# RFCORE_XREG register map
Vendor: Texas Instruments
Peripheral module from a debugger description file (folder cc2538).
Registers are 32-bit, access per field, no defined reset value unless marked. A register's access mark holds for its fields unless they carry their own. Offsets are as the file gives them; lines under a group give offsets from that group; [hi:lo] are bit positions; {n}, {i} and the like mark numbered series; 'fields as' and 'values as' point back to an identical list; <NAME> marks a mode.

## RFCORE_XREG — Register fields should be considered static unless otherwise noted as dynamic.
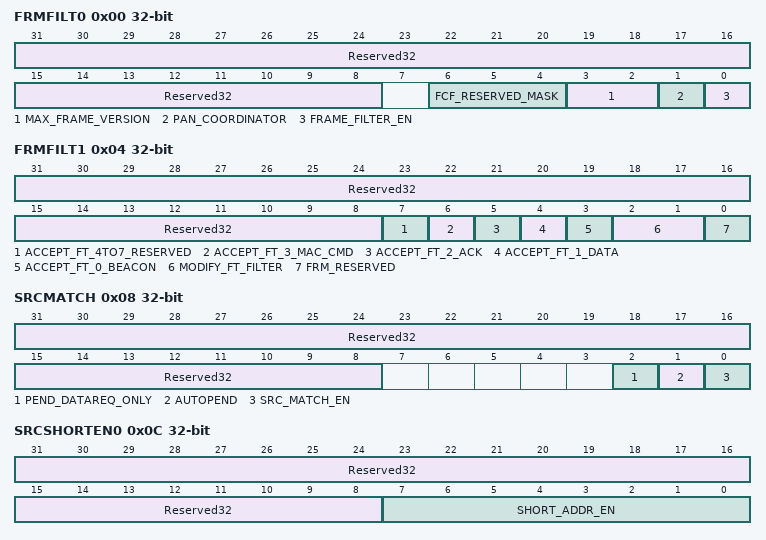
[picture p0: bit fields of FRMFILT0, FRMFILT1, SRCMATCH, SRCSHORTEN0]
0x00 FRMFILT0 — The frame filtering function rejects unintended frames as specified by IEEE 802.15.4, section 7.5.6.2, third filtering level. In addition, it provides filtering on: - The eight different frame types (see the FRMFILT1 register) - The reserved bits in the frame control field (FCF) The function is controlled by: - The FRMFILT0 and FRMFILT1 registers - The PAN_ID, SHORT_ADDR, and EXT_ADDR values in RAM
  [31:8] Reserved32 ro — This register is 8 bits in a 32-bit address space.
  [6:4] FCF_RESERVED_MASK rw — Used for filtering on the reserved part of the frame control field (FCF) FCF_RESERVED_MASK[2:0] is ANDed with FCF[9:7]. If the result is nonzero and frame filtering is enabled, the frame is rejected.
  [3:2] MAX_FRAME_VERSION rw — Used for filtering on the frame version field of the frame control field (FCF) If FCF[13:12] (the frame version subfield) is higher than MAX_FRAME_VERSION[1:0] and frame filtering is enabled, the frame is rejected.
  [1] PAN_COORDINATOR rw — Should be set high when the device is a PAN coordinator, to accept frames with no destination address (as specified in Section 7.5.6.2 in IEEE 802.15.4) 0: Device is not a PAN coordinator 1: Device is a PAN coordinator
  [0] FRAME_FILTER_EN rw — Enables frame filtering When this bit is set, the radio performs frame filtering as specified in section 7.5.6.2 of IEEE 802.15.4(b), third filtering level. FRMFILT0[6:1] and FRMFILT1[7:1], together with the local address information, define the behavior of the filtering algorithm. 0: Frame filtering off. (FRMFILT0[6:1], FRMFILT1[7:1] and SRCMATCH[2:0] are don't care.) 1: Frame filtering on.
0x04 FRMFILT1 — The frame filtering function rejects unintended frames as specified by IEEE 802.15.4, section 7.5.6.2, third filtering level. In addition, it provides filtering on: - The eight different frame types (see the FRMFILT1 register) - The reserved bits in the frame control field (FCF) The function is controlled by: - The FRMFILT0 and FRMFILT1 registers - The PAN_ID, SHORT_ADDR, and EXT_ADDR values in RAM
  [31:8] Reserved32 ro — This register is 8 bits in a 32-bit address space.
  [7] ACCEPT_FT_4TO7_RESERVED rw — Defines whether reserved frames are accepted or not. Reserved frames have frame type = 100, 101, 110, or 111. 0: Reject 1: Accept
  [6] ACCEPT_FT_3_MAC_CMD rw — Defines whether MAC command frames are accepted or not. MAC command frames have frame type = 011. 0: Reject 1: Accept
  [5] ACCEPT_FT_2_ACK rw — Defines whether acknowledgment frames are accepted or not. Acknowledgement frames have frame type = 010. 0: Reject 1: Accept
  [4] ACCEPT_FT_1_DATA rw — Defines whether data frames are accepted or not. Data frames have frame type = 001. 0: Reject 1: Accept
  [3] ACCEPT_FT_0_BEACON rw — Defines whether beacon frames are accepted or not. Beacon frames have frame type = 000. 0: Reject 1: Accept
  [2:1] MODIFY_FT_FILTER rw — These bits are used to modify the frame type field of a received frame before frame type filtering is performed. The modification does not influence the frame that is written to the RX FIFO. 00: Leave the frame type as it is. 01: Invert MSB of the frame type. 10: Set MSB of the frame type to 0. 11: Set MSB of the frame type to 1.
  [0] FRM_RESERVED rw — Reserved. Always write 0.
0x08 SRCMATCH — Source address matching and pending bits
  [31:8] Reserved32 ro — This register is 8 bits in a 32-bit address space.
  [2] PEND_DATAREQ_ONLY rw — When this bit is set, the AUTOPEND function also requires that the received frame is a DATA REQUEST MAC command frame.
  [1] AUTOPEND rw — Automatic acknowledgment pending flag enable When a frame is received, the pending bit in the (possibly) returned acknowledgment is set automatically when the following conditions are met: - FRMFILT.FRAME_FILTER_EN is set. - SRCMATCH.SRC_MATCH_EN is set. - SRCMATCH.AUTOPEND is set. - The received frame matches the current SRCMATCH.PEND_DATAREQ_ONLY setting. - The received source address matches at least one source match table entry, which is enabled in SHORT_ADDR_EN and SHORT_PEND_EN or in EXT_ADDR_EN and EXT_PEND_EN.
  [0] SRC_MATCH_EN rw — Source address matching enable (requires that FRMFILT.FRAME_FILTER_EN = 1)
0x0C SRCSHORTEN0 — Short address matching
  [31:8] Reserved32 ro — This register is 8 bits in a 32-bit address space.
  [7:0] SHORT_ADDR_EN rw — 7:0 part of the 24-bit word SHORT_ADDR_EN that enables or disables source address matching for each of the 24 short address table entries Optional safety feature: To ensure that an entry in the source matching table is not used while it is being updated, set the corresponding SHORT_ADDR_EN bit to 0 while updating.
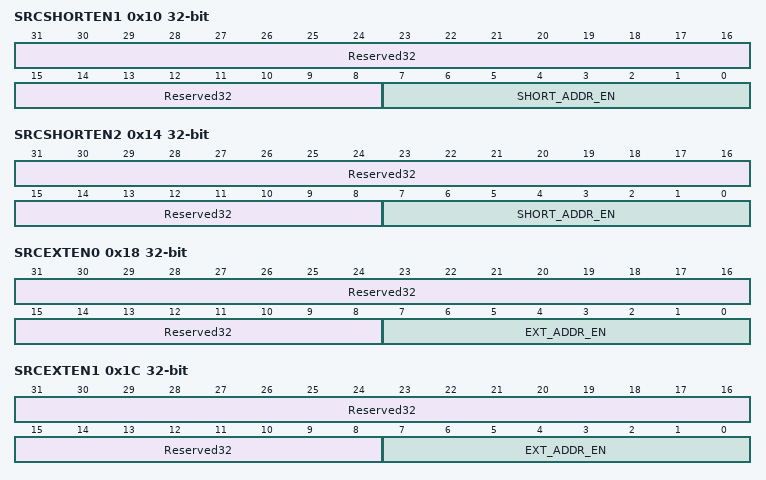
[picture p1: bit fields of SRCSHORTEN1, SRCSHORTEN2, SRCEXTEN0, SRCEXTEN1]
0x10 SRCSHORTEN1 — Short address matching
  [31:8] Reserved32 ro — This register is 8 bits in a 32-bit address space.
  [7:0] SHORT_ADDR_EN rw — 15:8 part of the 24-bit word SHORT_ADDR_EN See description of SRCSHORTEN0.SHORT_ADDR_EN.
0x14 SRCSHORTEN2 — Short address matching
  [31:8] Reserved32 ro — This register is 8 bits in a 32-bit address space.
  [7:0] SHORT_ADDR_EN rw — 23:16 part of the 24-bit word SHORT_ADDR_EN See description of SRCSHORTEN0.SHORT_ADDR_EN.
0x18 SRCEXTEN0 — Extended address matching
  [31:8] Reserved32 ro — This register is 8 bits in a 32-bit address space.
  [7:0] EXT_ADDR_EN rw — 7:0 part of the 24-bit word EXT_ADDR_EN that enables or disables source address matching for each of the 12 extended address table entries Write access: Extended address enable for table entry n (0 to 11) is mapped to EXT_ADDR_EN[2n]. All EXT_ADDR_EN[2n + 1] bits are read only. Read access: Extended address enable for table entry n (0 to 11) is mapped to EXT_ADDR_EN[2n] and EXT_ADDR_EN[2n + 1]. Optional safety feature: To ensure that an entry in the source matching table is not used while it is being updated, set the corresponding EXT_ADDR_EN bit to 0 while updating.
0x1C SRCEXTEN1 — Extended address matching
  [31:8] Reserved32 ro — This register is 8 bits in a 32-bit address space.
  [7:0] EXT_ADDR_EN rw — 15:8 part of the 24-bit word EXT_ADDR_EN See description of SRCEXTEN0.EXT_ADDR_EN.
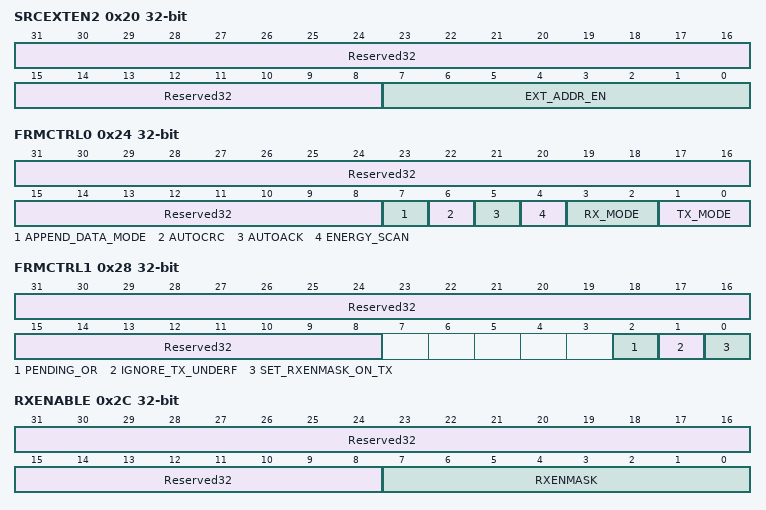
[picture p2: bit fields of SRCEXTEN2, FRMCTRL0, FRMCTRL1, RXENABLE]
0x20 SRCEXTEN2 — Extended address matching
  [31:8] Reserved32 ro — This register is 8 bits in a 32-bit address space.
  [7:0] EXT_ADDR_EN rw — 23:16 part of the 24-bit word EXT_ADDR_EN See description of SRCEXTEN0.EXT_ADDR_EN.
0x24 FRMCTRL0 — Frame handling
  [31:8] Reserved32 ro — This register is 8 bits in a 32-bit address space.
  [7] APPEND_DATA_MODE rw — When AUTOCRC = 0: Don't care When AUTOCRC = 1: 0: RSSI + The CRC_OK bit and the 7-bit correlation value are appended at the end of each received frame 1: RSSI + The CRC_OK bit and the 7-bit SRCRESINDEX are appended at the end of each received frame.
  [6] AUTOCRC rw — In TX 1: A CRC-16 (ITU-T) is generated in hardware and appended to the transmitted frame. There is no need to write the last 2 bytes to TXBUF. 0: No CRC-16 is appended to the frame. The last 2 bytes of the frame must be generated manually and written to TXBUF (if not, TX_UNDERFLOW occurs). In RX 1: The CRC-16 is checked in hardware, and replaced in the RXFIFO by a 16-bit status word which contains a CRC OK bit. The status word is controllable through APPEND_DATA_MODE. 0: The last 2 bytes of the frame (CRC-16 field) are stored in the RX FIFO. The CRC (if any) must be done manually. This setting does not influence acknowledgment transmission (including AUTOACK).
  [5] AUTOACK rw — Defines whether the radio automatically transmits acknowledge frames or not. When autoack is enabled, all frames that are accepted by address filtering, have the acknowledge request flag set, and have a valid CRC are automatically acknowledged 12 symbol periods after being received. 0: Autoack disabled 1: Autoack enabled
  [4] ENERGY_SCAN rw — Defines whether the RSSI register contains the most-recent signal strength or the peak signal strength since the energy scan was enabled. 0: Most-recent signal strength 1: Peak signal strength
  [3:2] RX_MODE rw — Set RX modes. 00: Normal operation, use RX FIFO 01: Receive serial mode, output received data on to IOC; infinite RX 10: RX FIFO looping ignore overflow in RX FIFO; infinite reception 11: Same as normal operation except that symbol search is disabled. Can be used for RSSI or CCA measurements when finding symbol is not desired.
  [1:0] TX_MODE rw — Set test modes for TX. 00: Normal operation, transmit TX FIFO 01: Reserved, should not be used 10: TX FIFO looping ignore underflow in TX FIFO and read cyclic; infinite transmission 11: Send random data from CRC; infinite transmission
0x28 FRMCTRL1 rw — Frame handling
  [31:8] Reserved32 — This register is 8 bits in a 32-bit address space.
  [2] PENDING_OR — Defines whether the pending data bit in outgoing acknowledgment frames is always set to 1 or controlled by the main FSM and the address filtering 0: Pending data bit is controlled by main FSM and address filtering. 1: Pending data bit is always 1.
  [1] IGNORE_TX_UNDERF — Defines whether or not TX underflow should be ignored 0: Normal TX operation. TX underflow is detected and TX is aborted if underflow occurs. 1: Ignore TX underflow. Transmit the number of bytes given by the frame-length field.
  [0] SET_RXENMASK_ON_TX — Defines whether STXON sets bit 6 in the RXENABLE register or leaves it unchanged 0: Does not affect RXENABLE 1: Sets bit 6 in RXENABLE. Used for backward compatibility with the CC2420.
0x2C RXENABLE ro — RX enabling
  [31:8] Reserved32 — This register is 8 bits in a 32-bit address space.
  [7:0] RXENMASK — RXENABLE enables the receiver. A nonzero value in this register causes FFCTRL to enable the receiver when in idle, after transmission and after acknowledgement transmission. The following strobes can modify RXENMASK: SRXON: Set bit 7 in RXENMASK. STXON: Set bit 6 in RXENMASK if SET_RXENMASK_ON_TX = 1. SRFOFF: Clears all bits in RXENMASK. SRXMASKBITSET: Set bit 5 in RXENMASK. SRXMASKBITCLR: Clear bit 5 in RXENMASK. There could be conflicts between the CSP and xreg_bus write operations if both operations try to modify RXENMASK simultaneously. To handle the case of simultaneous access to RXENMASK the following rules apply: - If the two sources agree (they modify different parts of the register) both of their requests to modify RXENMASK are processed. - If both operations try to modify the mask simultaneously, bus write operations to RXMASKSET and RXMASKCLR have priority over the CSP. This situation must be avoided.
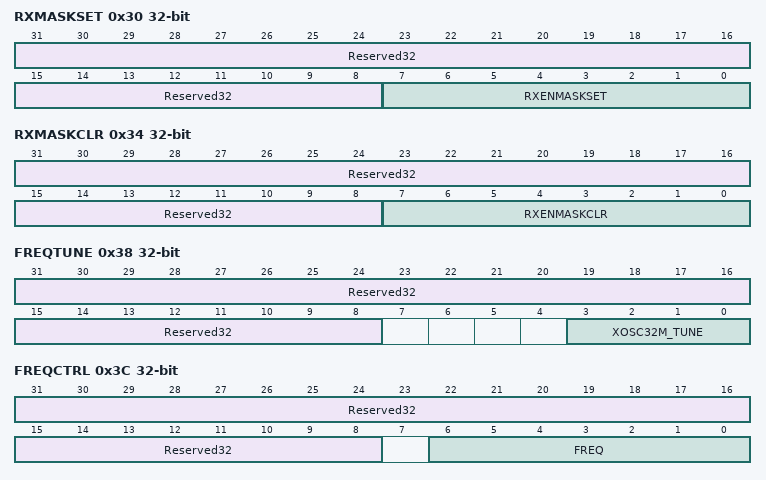
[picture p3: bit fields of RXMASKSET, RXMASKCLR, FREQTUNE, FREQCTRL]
0x30 RXMASKSET — RX enabling
  [31:8] Reserved32 ro — This register is 8 bits in a 32-bit address space.
  [7:0] RXENMASKSET rw — When written, the written data is ORed with the RXENMASK and stored in RXENMASK.
0x34 RXMASKCLR — RX disabling
  [31:8] Reserved32 ro — This register is 8 bits in a 32-bit address space.
  [7:0] RXENMASKCLR rw — When written, the written data is inverted and ANDed with the RXENMASK and stored in RXENMASK. For example, if 1 is written to one or more bit positions in this register, the corresponding bits are cleared in RXENMASK.
0x38 FREQTUNE — Crystal oscillator frequency tuning
  [31:8] Reserved32 ro — This register is 8 bits in a 32-bit address space.
  [3:0] XOSC32M_TUNE rw — Tune crystal oscillator The default setting 1111 leaves the XOSC untuned. Changing the setting from the default setting (1111) switches in extra capacitance to the oscillator, effectively lowering the XOSC frequency. Hence, a higher setting gives a higher frequency.
0x3C FREQCTRL — Controls the RF frequency
  [31:8] Reserved32 ro — This register is 8 bits in a 32-bit address space.
  [6:0] FREQ rw — Frequency control word The frequency word in FREQ[6:0] is an offset value from 2394 (fRF = FREQ[6 0] + 2394). The RF-frequency is specified from 2405 to 2480 MHz in 1-MHz steps; hence, the only valid settings for FREQ[6:0] are 11 to 86 (11 + 2394 = 2405 and 86 + 2394 = 2480). The device supports the frequency range from 2394 to 2507 MHz. Consequently, the usable settings for FREQ[6:0] are 0 to 113. Settings outside of the usable range (114 to 127) give a frequency of 2507 MHz. IEEE 802.15.4-2006 specifies a frequency range from 2405 MHz to 2480 MHz with 16 channels 5 MHz apart. The channels are numbered 11 through 26. For an IEEE 802.15.4-2006 compliant system, the only valid settings are thus FREQ[6:0] = 11 + 5 (channel number - 11).
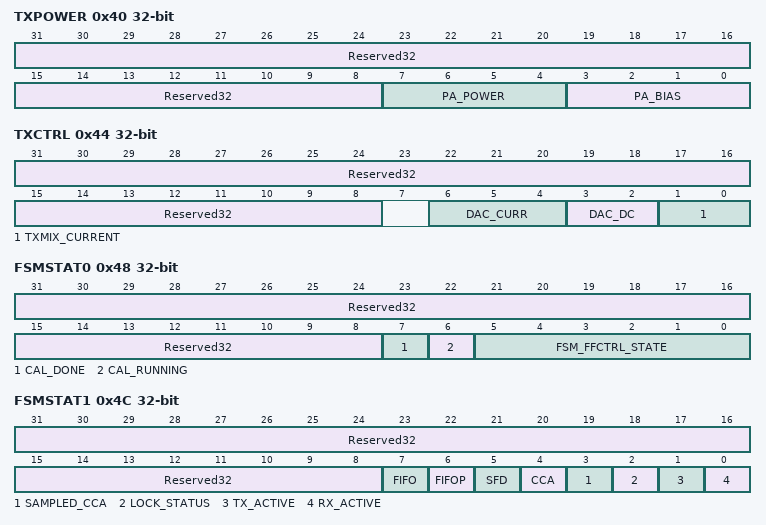
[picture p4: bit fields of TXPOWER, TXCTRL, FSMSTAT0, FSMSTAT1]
0x40 TXPOWER access not given — Controls the output power
  [31:8] Reserved32 ro — This register is 8 bits in a 32-bit address space.
  [7:4] PA_POWER — PA power control (access NA)
  [3:0] PA_BIAS rw — PA bias control
0x44 TXCTRL — Controls the TX settings
  [31:8] Reserved32 ro — This register is 8 bits in a 32-bit address space.
  [6:4] DAC_CURR rw — Change the current in the DAC.
  [3:2] DAC_DC rw — Adjusts the DC level to the TX mixer.
  [1:0] TXMIX_CURRENT rw — Transmit mixers core current Current increases with increasing setting.
0x48 FSMSTAT0 ro — Radio status register
  [31:8] Reserved32 — This register is 8 bits in a 32-bit address space.
  [7] CAL_DONE — Frequency synthesis calibration has been performed since the last time the FS was turned on.
  [6] CAL_RUNNING — Frequency synthesis calibration status 0: Calibration is complete or not started. 1: Calibration is in progress.
  [5:0] FSM_FFCTRL_STATE — Gives the current state of the FIFO and frame control (FFCTRL) finite state-machine.
0x4C FSMSTAT1 ro — Radio status register
  [31:8] Reserved32 — This register is 8 bits in a 32-bit address space.
  [7] FIFO — FIFO is high when there is data in the RX FIFO. FIFO is low during RX FIFO overflow.
  [6] FIFOP — FIFOP is set high when there are at more than FIFOP_THR bytes of data in the RX FIFO that has passed frame filtering. FIFOP is set high when there is at least one complete frame in the RX FIFO. FIFOP is high during RX FIFO overflow.
  [5] SFD — In TX 0: When a complete frame with SFD was sent or no SFD was sent 1: SFD was sent. In RX 0: When a complete frame was received or no SFD was received 1: SFD was received.
  [4] CCA — Clear channel assessment Dependent on CCA_MODE settings. See CCACTRL1 for details.
  [3] SAMPLED_CCA — Contains a sampled value of the CCA The value is updated when a SSAMPLECCA or STXONCCA strobe is issued.
  [2] LOCK_STATUS — 1 when PLL is in lock; otherwise 0
  [1] TX_ACTIVE — Status signal Active when FFC is in one of the transmit states
  [0] RX_ACTIVE — Status signal Active when FFC is in one of the receive states
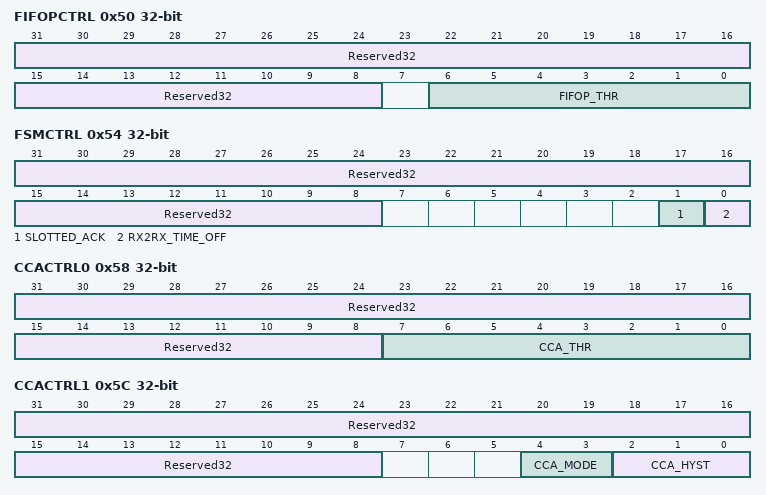
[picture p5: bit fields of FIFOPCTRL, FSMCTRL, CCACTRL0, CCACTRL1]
0x50 FIFOPCTRL — FIFOP threshold
  [31:8] Reserved32 ro — This register is 8 bits in a 32-bit address space.
  [6:0] FIFOP_THR rw — Threshold used when generating FIFOP signal
0x54 FSMCTRL — FSM options
  [31:8] Reserved32 ro — This register is 8 bits in a 32-bit address space.
  [1] SLOTTED_ACK rw — Controls timing of transmission of acknowledge frames 0: The acknowledge frame is sent 12 symbol periods after the end of the received frame which requests the aknowledge. 1: The acknowledge frame is sent at the first backoff-slot boundary more than 12 symbol periods after the end of the received frame which requests the aknowledge.
  [0] RX2RX_TIME_OFF rw — Defines whether or not a 12-symbol time-out should be used after frame reception has ended. 0: No time-out 1: 12-symbol-period time-out
0x58 CCACTRL0 — CCA threshold
  [31:8] Reserved32 ro — This register is 8 bits in a 32-bit address space.
  [7:0] CCA_THR rw — Clear-channel-assessment threshold value, signed 2's-complement number for comparison with the RSSI. The unit is 1 dB, offset is 73dB The CCA signal goes high when the received signal is below this value. The CCA signal is available on the CCA pin and in the FSMSTAT1 register. The value must never be set lower than CCA_HYST - 128 to avoid erroneous behavior of the CCA signal. Note: The reset value translates to an input level of approximately -32 - 73 = -105 dBm, which is well below the sensitivity limit. This means that the CCA signal never indicates a clear channel. This register should be updated to 0xF8, which translates to an input level of about -8 - 73 = -81 dBm.
0x5C CCACTRL1 — Other CCA Options
  [31:8] Reserved32 ro — This register is 8 bits in a 32-bit address space.
  [4:3] CCA_MODE rw — 00: CCA always set to 1 01: CCA = 1 when RSSI < CCA_THR - CCA_HYST; CCA = 0 when RSSI >= CCA_THR 10: CCA = 1 when not receiving a frame, else CCA = 0 11: CCA = 1 when RSSI < CCA_THR - CCA_HYST and not receiving a frame; CCA = 0 when RSSI >= CCA_THR or when receiving a frame
  [2:0] CCA_HYST rw — Sets the level of CCA hysteresis. Unsigned values given in dB
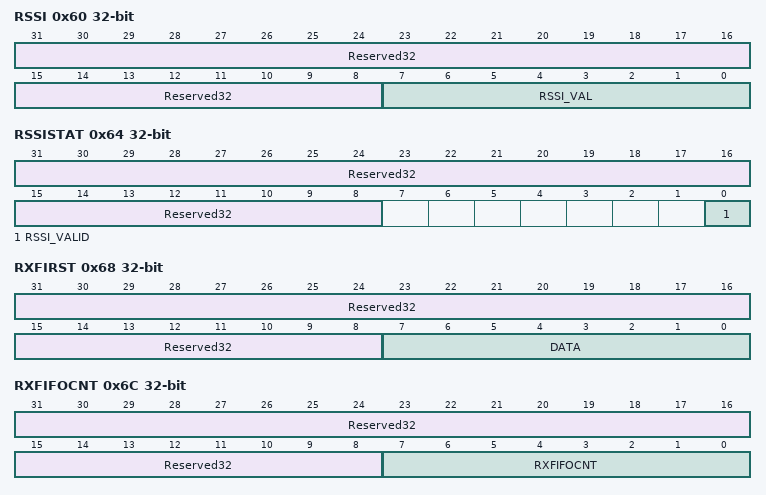
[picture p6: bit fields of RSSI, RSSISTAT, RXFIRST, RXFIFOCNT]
0x60 RSSI ro — RSSI status register
  [31:8] Reserved32 — This register is 8 bits in a 32-bit address space.
  [7:0] RSSI_VAL — RSSI estimate on a logarithmic scale, signed number on 2's complement Unit is 1 dB, offset is 73dB. The RSSI value is averaged over eight symbol periods. The RSSI_VALID status bit should be checked before reading RSSI_VAL for the first time. The reset value of -128 also indicates that the RSSI value is invalid.
0x64 RSSISTAT ro — RSSI valid status register
  [31:8] Reserved32 — This register is 8 bits in a 32-bit address space.
  [0] RSSI_VALID — RSSI value is valid. Occurs eight symbol periods after entering RX.
0x68 RXFIRST ro — First byte in RX FIFO
  [31:8] Reserved32 — This register is 8 bits in a 32-bit address space.
  [7:0] DATA — First byte of the RX FIFO Note: Reading this register does not modify the contents of the FIFO.
0x6C RXFIFOCNT ro — Number of bytes in RX FIFO
  [31:8] Reserved32 — This register is 8 bits in a 32-bit address space.
  [7:0] RXFIFOCNT — Number of bytes in the RX FIFO (unsigned integer)
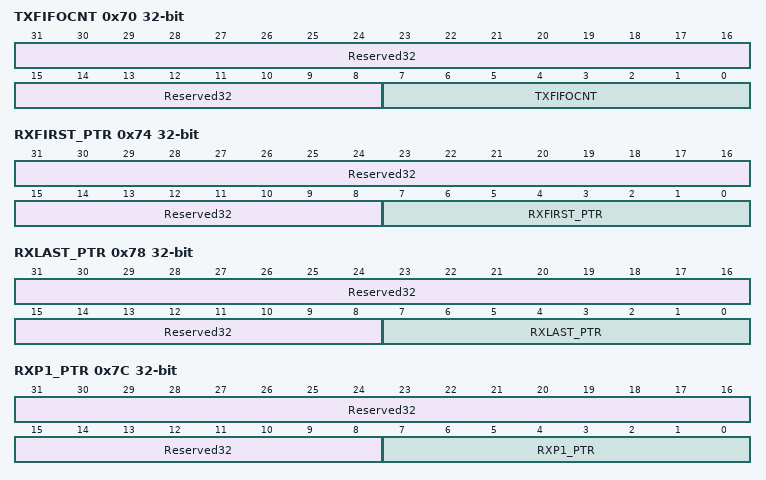
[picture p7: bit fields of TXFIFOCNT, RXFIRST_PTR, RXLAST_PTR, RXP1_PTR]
0x70 TXFIFOCNT ro — Number of bytes in TX FIFO
  [31:8] Reserved32 — This register is 8 bits in a 32-bit address space.
  [7:0] TXFIFOCNT — Number of bytes in the TX FIFO (unsigned integer)
0x74 RXFIRST_PTR ro — RX FIFO pointer
  [31:8] Reserved32 — This register is 8 bits in a 32-bit address space.
  [7:0] RXFIRST_PTR — RAM address offset of the first byte in the RX FIFO
0x78 RXLAST_PTR ro — RX FIFO pointer
  [31:8] Reserved32 — This register is 8 bits in a 32-bit address space.
  [7:0] RXLAST_PTR — RAM address offset of the last byte + 1 byte in the RX FIFO
0x7C RXP1_PTR ro — RX FIFO pointer
  [31:8] Reserved32 — This register is 8 bits in a 32-bit address space.
  [7:0] RXP1_PTR — RAM address offset of the first byte of the first frame in the RX FIFO
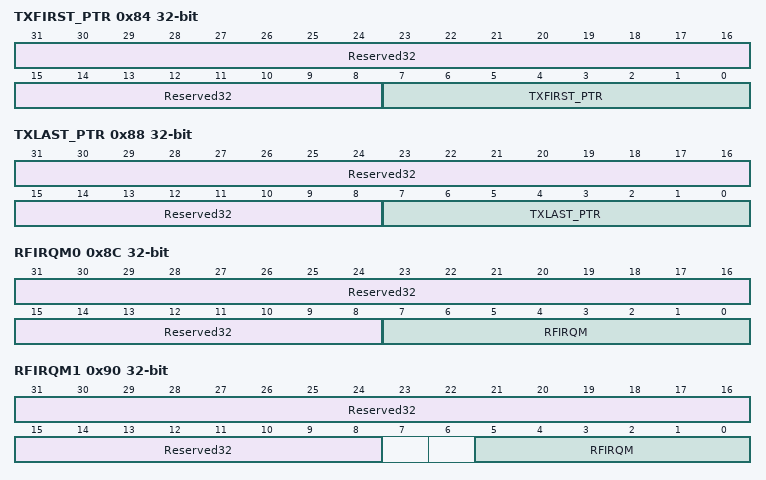
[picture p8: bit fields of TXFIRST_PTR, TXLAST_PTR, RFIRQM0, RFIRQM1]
0x84 TXFIRST_PTR ro — TX FIFO pointer
  [31:8] Reserved32 — This register is 8 bits in a 32-bit address space.
  [7:0] TXFIRST_PTR — RAM address offset of the next byte to be transmitted from the TX FIFO
0x88 TXLAST_PTR ro — TX FIFO pointer
  [31:8] Reserved32 — This register is 8 bits in a 32-bit address space.
  [7:0] TXLAST_PTR — RAM address offset of the last byte + 1 byte of the TX FIFO
0x8C RFIRQM0 — RF interrupt masks
  [31:8] Reserved32 ro — This register is 8 bits in a 32-bit address space.
  [7:0] RFIRQM rw — Bit mask is masking out interrupt sources. Bit position: 7: RXMASKZERO 6: RXPKTDONE 5: FRAME_ACCEPTED 4: SRC_MATCH_FOUND 3: SRC_MATCH_DONE 2: FIFOP 1: SFD 0: ACT_UNUSED
0x90 RFIRQM1 — RF interrupt masks
  [31:8] Reserved32 ro — This register is 8 bits in a 32-bit address space.
  [5:0] RFIRQM rw — Bit mask is masking out interrupt sources. Bit position: 5: CSP_WAIT 4: CSP_STOP 3: CSP_MANINT 2: RF_IDLE 1: TXDONE 0: TXACKDONE
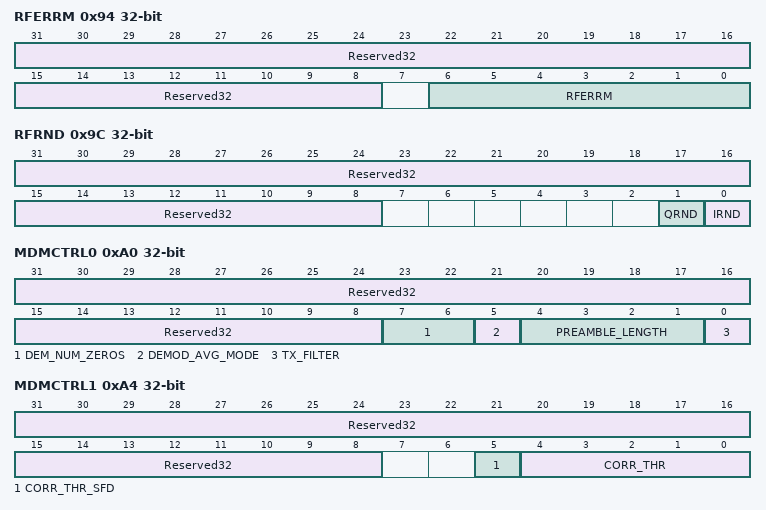
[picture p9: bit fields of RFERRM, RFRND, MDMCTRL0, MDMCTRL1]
0x94 RFERRM — RF error interrupt mask
  [31:8] Reserved32 ro — This register is 8 bits in a 32-bit address space.
  [6:0] RFERRM rw — Bit mask is masking out interrupt sources. Bit position: 6: STROBE_ERR 5: TXUNDERF 4: TXOVERF 3: RXUNDERF 2: RXOVERF 1: RXABO 0: NLOCK
0x9C RFRND ro — Random data
  [31:8] Reserved32 — This register is 8 bits in a 32-bit address space.
  [1] QRND — Random bit from the Q channel of the receiver
  [0] IRND — Random bit from the I channel of the receiver
0xA0 MDMCTRL0 — Controls modem
  [31:8] Reserved32 ro — This register is 8 bits in a 32-bit address space.
  [7:6] DEM_NUM_ZEROS rw — Sets how many zero symbols must be detected before the sync word when searching for sync. Only one zero symbol is required to have a correlation value above the correlation threshold set in the MDMCTRL1 register. 00: Reserved 01: 1 zero symbol 10: 2 zero symbols 11: 3 zero symbols
  [5] DEMOD_AVG_MODE rw — Defines the behavior or the frequency offset averaging filter. 0: Lock average level after preamble match. Restart frequency offset calibration when searching for the next frame. 1: Continuously update average level.
  [4:1] PREAMBLE_LENGTH rw — The number of preamble bytes (two zero-symbols) to be sent in TX mode before the SFD, encoded in steps of 2 symbols (1 byte). The reset value of 2 is compliant with IEEE 802.15.4. 0000: 2 leading-zero bytes 0001: 3 leading-zero bytes 0010: 4 leading-zero bytes ... 1111: 17 leading-zero bytes
  [0] TX_FILTER rw — Defines the kind of TX filter that is used. The normal TX filter is as defined by the IEEE 802.15.4 standard. Extra filtering may be applied to lower the out-of-band emissions. 0: Normal TX filtering 1: Enable extra filtering
0xA4 MDMCTRL1 — Controls modem
  [31:8] Reserved32 ro — This register is 8 bits in a 32-bit address space.
  [5] CORR_THR_SFD rw — Defines requirements for SFD detection: 0: The correlation value of one of the zero symbols of the preamble must be above the correlation threshold. 1: The correlation value of one zero symbol of the preamble and both symbols in the SFD must be above the correlation threshold.
  [4:0] CORR_THR rw — Demodulator correlator threshold value, required before SFD search. Threshold value adjusts how the receiver synchronizes to data from the radio. If the threshold is set too low, sync can more easily be found on noise. If set too high, the sensitivity is reduced, but sync is not likely to be found on noise. In combination with DEM_NUM_ZEROS, the system can be tuned so sensitivity is high with less sync found on noise.
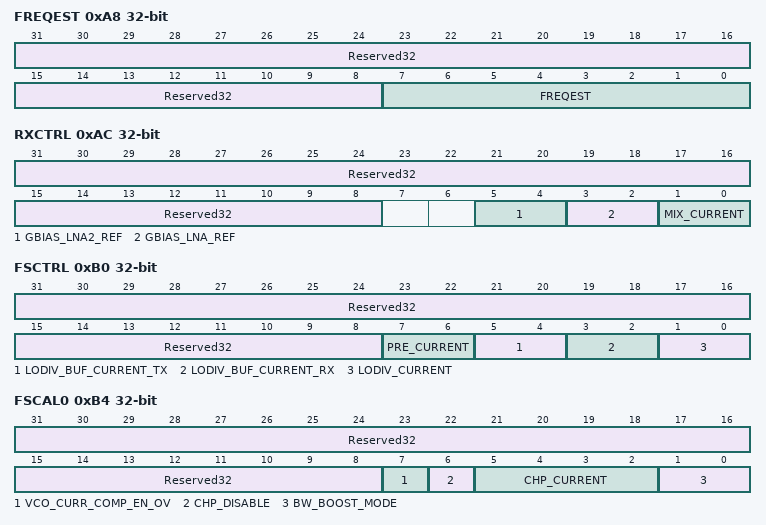
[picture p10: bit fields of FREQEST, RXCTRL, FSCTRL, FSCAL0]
0xA8 FREQEST ro — Estimated RF frequency offset
  [31:8] Reserved32 — This register is 8 bits in a 32-bit address space.
  [7:0] FREQEST — Signed 2's-complement value. Contains an estimate of the frequency offset between carrier and the receiver LO. The offset frequency is FREQEST x 7800 Hz. DEM_AVG_MODE controls when this estimate is updated. If DEM_AVG_MODE = 0, it is updated until sync is found. Then the frequency offset estimate is frozen until the end of the received frame. If DEM_AVG_MODE = 1, it is updated as long as the demodulator is enabled. To calculate the correct value, one must use an offset (FREQEST_offset), which can be found in the device data sheet. Real FREQEST value = FREQEST - FREQEST_offset.
0xAC RXCTRL — Tune receive section
  [31:8] Reserved32 ro — This register is 8 bits in a 32-bit address space.
  [5:4] GBIAS_LNA2_REF rw — Adjusts front-end LNA2/mixer PTAT current output (from M = 3 to M = 6), default: M = 5
  [3:2] GBIAS_LNA_REF rw — Adjusts front-end LNA PTAT current output (from M = 3 to M = 6), default: M = 5
  [1:0] MIX_CURRENT rw — Control of the output current from the receiver mixers The current increases with increasing setting set.
0xB0 FSCTRL — Tune frequency synthesizer
  [31:8] Reserved32 ro — This register is 8 bits in a 32-bit address space.
  [7:6] PRE_CURRENT rw — Prescaler current setting
  [5:4] LODIV_BUF_CURRENT_TX rw — Adjusts current in mixer and PA buffers Used when TX_ACTIVE = 1
  [3:2] LODIV_BUF_CURRENT_RX rw — Adjusts current in mixer and PA buffers Used when TX_ACTIVE = 0
  [1:0] LODIV_CURRENT rw — Adjusts divider currents, except mixer and PA buffers
0xB4 FSCAL0 — Tune frequency calibration
  [31:8] Reserved32 ro — This register is 8 bits in a 32-bit address space.
  [7] VCO_CURR_COMP_EN_OV rw — Force on the current comparator in the VCO. This signal is ORed with the signal coming from the calibration module.
  [6] CHP_DISABLE rw — Set this bit to manually disable charge pump by masking the up and down pulses from the phase detector.
  [5:2] CHP_CURRENT rw — Digital bit vector defining the charge-pump output current on an exponential scale If FFC_BW_BOOST = 0, the read value is the value stored in CHP_CURRENT. If FFC_BW_BOOST = 1, the read value is CHP_CURRENT + 4. If the addition causes overflow, the signal is saturated.
  [1:0] BW_BOOST_MODE rw — Control signal Defines the synthesizer boost mode 00: No BW_BOOST 01: BW_BOOST is high during calibration and approximately 30 us into the settling. 10: BW_BOOST is always on (or high). 11: Reserved
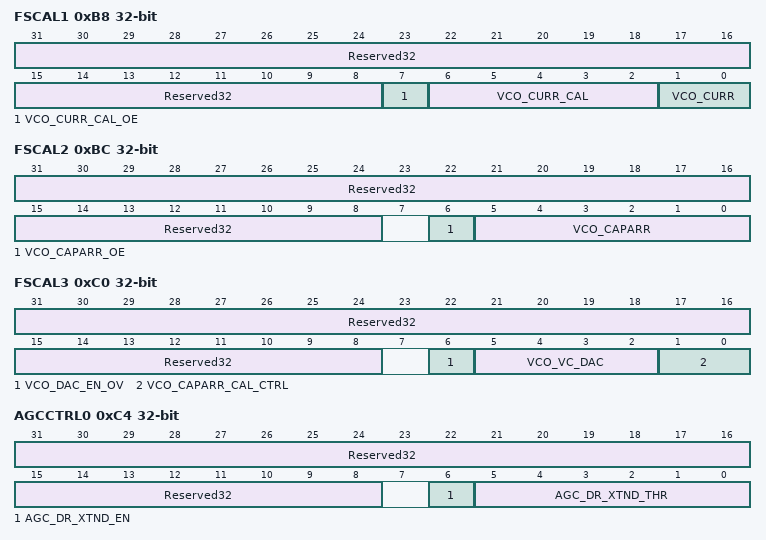
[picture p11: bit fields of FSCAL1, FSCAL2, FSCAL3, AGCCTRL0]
0xB8 FSCAL1 — Tune frequency calibration
  [31:8] Reserved32 ro — This register is 8 bits in a 32-bit address space.
  [7] VCO_CURR_CAL_OE rw — Override current calibration
  [6:2] VCO_CURR_CAL rw — Calibration result Override value if VCO_CURR_CAL_OE = 1
  [1:0] VCO_CURR rw — Defines current in VCO core Sets the multiplier between calibrated current and VCO current.
0xBC FSCAL2 — Tune frequency calibration
  [31:8] Reserved32 ro — This register is 8 bits in a 32-bit address space.
  [6] VCO_CAPARR_OE rw — Override the calibration result with the value from VCO_CAPARR[5:0].
  [5:0] VCO_CAPARR rw — VCO capacitor array setting Programmed during calibration Override value when VCO_CAPARR_OE = 1
0xC0 FSCAL3 — Tune frequency calibration
  [31:8] Reserved32 ro — This register is 8 bits in a 32-bit address space.
  [6] VCO_DAC_EN_OV rw — Enables the VCO DAC when 1
  [5:2] VCO_VC_DAC rw — Bit vector for programming varactor control voltage from VC DAC
  [1:0] VCO_CAPARR_CAL_CTRL rw — Calibration accuracy setting for the cap_array calibration part of the calibration 00: 80 XOSC periods 01: 100 XOSC periods 10: 125 XOSC periods 11: 250 XOSC periods
0xC4 AGCCTRL0 — AGC dynamic range control
  [31:8] Reserved32 ro — This register is 8 bits in a 32-bit address space.
  [6] AGC_DR_XTND_EN rw — 0: The AGC performs no adjustment of attenuation in the AAF. 1: The AGC adjusts the gain in the AAF to achieve extra dynamic range for the receiver.
  [5:0] AGC_DR_XTND_THR rw — If the measured error between the AGC reference magnitude and the actual magnitude in dB is larger than this threshold, the extra attenuation is enabled in the front end. This threshold must be set higher than 0x0C. This feature is enabled by AGC_DR_XTND_EN.
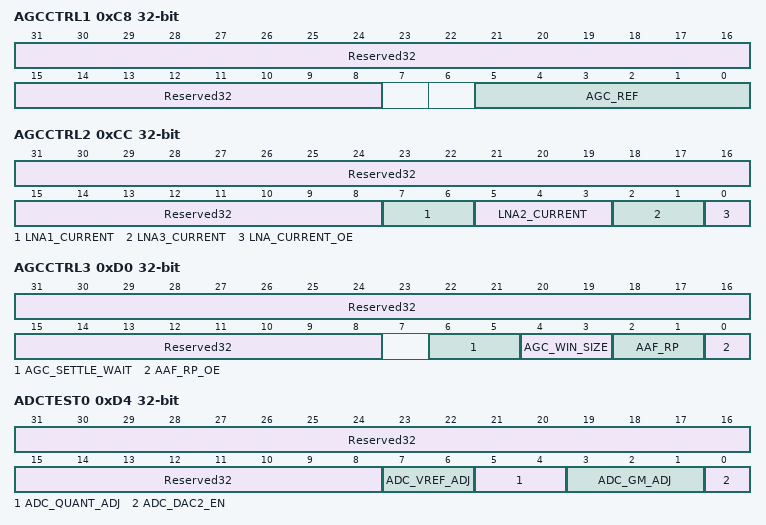
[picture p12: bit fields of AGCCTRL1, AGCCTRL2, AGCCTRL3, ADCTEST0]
0xC8 AGCCTRL1 — AGC reference level
  [31:8] Reserved32 ro — This register is 8 bits in a 32-bit address space.
  [5:0] AGC_REF rw — Target value for the AGC control loop, given in 1-dB steps
0xCC AGCCTRL2 — AGC gain override
  [31:8] Reserved32 ro — This register is 8 bits in a 32-bit address space.
  [7:6] LNA1_CURRENT rw — Overrride value for LNA 1 Used only when LNA_CURRENT_OE = 1 When read, this register returns the current applied gain setting. 00: 0-dB gain (reference level) 01: 3-dB gain 10: Reserved 11: 6-dB gain
  [5:3] LNA2_CURRENT rw — Overrride value for LNA 2 Used only when LNA_CURRENT_OE = 1 When read, this register returns the current applied gain setting. 000: 0-dB gain (reference level) 001: 3-dB gain 010: 6-dB gain 011: 9-dB gain 100: 12-dB gain 101: 15-dB gain 110: 18-dB gain 111: 21-dB gain
  [2:1] LNA3_CURRENT rw — Overrride value for LNA 3 Used only when LNA_CURRENT_OE = 1 When read, this register returns the current applied gain setting. 00: 0-dB gain (reference level) 01: 3-dB gain 10: 6-dB gain 11: 9-dB gain
  [0] LNA_CURRENT_OE rw — Write 1 to override the AGC LNA current setting with the values above (LNA1_CURRENT, LNA2_CURRENT, and LNA3_CURRENT).
0xD0 AGCCTRL3 — AGC control
  [31:8] Reserved32 ro — This register is 8 bits in a 32-bit address space.
  [6:5] AGC_SETTLE_WAIT rw — Timing for AGC to wait for analog gain to settle after a gain change. During this period, the energy measurement in the AGC is paused. 00: 15 periods 01: 20 periods 10: 25 periods 11: 30 periods
  [4:3] AGC_WIN_SIZE rw — Window size for the accumulate-and-dump function in the AGC. 00: 16 samples 01: 32 samples 10: 64 samples 11: 128 samples
  [2:1] AAF_RP rw — Overrides the control signals of the AGC to AAF when AAF_RP_OE = 1. When read, it returns the applied signal to the AAF. 00: 9-dB attenuation in AAF 01: 6-dB attenuation in AAF 10: 3-dB attenuation in AAF 11: 0-dB attenuation in AAF (reference level)
  [0] AAF_RP_OE rw — Override the AAF control signals of the AGC with the values stored in AAF_RP.
0xD4 ADCTEST0 — ADC tuning
  [31:8] Reserved32 ro — This register is 8 bits in a 32-bit address space.
  [7:6] ADC_VREF_ADJ rw — Quantizer threshold control for test and debug
  [5:4] ADC_QUANT_ADJ rw — Quantizer threshold control for test and debug
  [3:1] ADC_GM_ADJ rw — Gm-control for test and debug
  [0] ADC_DAC2_EN rw — Enables DAC2 for enhanced ADC stability
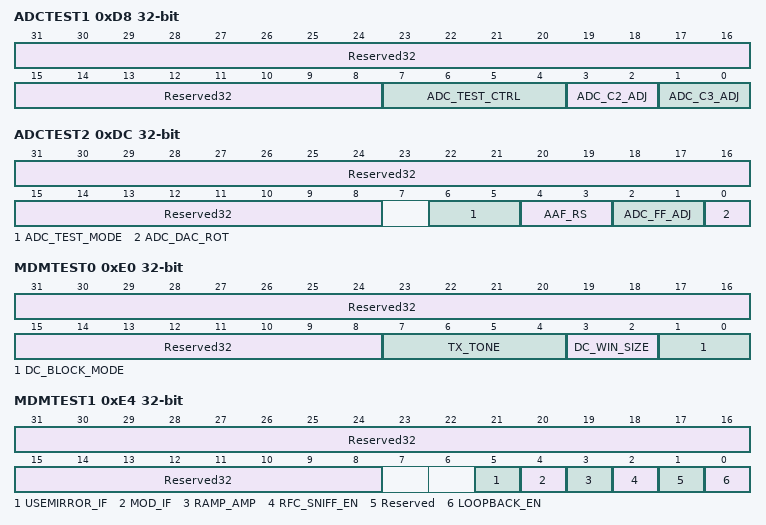
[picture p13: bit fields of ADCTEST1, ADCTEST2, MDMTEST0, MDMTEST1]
0xD8 ADCTEST1 — ADC tuning
  [31:8] Reserved32 ro — This register is 8 bits in a 32-bit address space.
  [7:4] ADC_TEST_CTRL rw — ADC test mode selector
  [3:2] ADC_C2_ADJ rw — Used to adjust capacitor values in ADC
  [1:0] ADC_C3_ADJ rw — Used to adjust capacitor values in ADC
0xDC ADCTEST2 — ADC tuning
  [31:8] Reserved32 ro — This register is 8 bits in a 32-bit address space.
  [6:5] ADC_TEST_MODE rw — Test mode to enable output of ADC data from demodulator. When enabled, raw ADC data is clocked out on the GPIO pins. 00: Test mode disabled 01: Data from the I and Q ADCs are output (data rate 76 MHz) 10: Data from the I ADC is output. Two and two ADC samples grouped (data rate 38 MHz) 11: Data from the Q ADC is output. Two and two ADC samples grouped (data rate 38 MHz)
  [4:3] AAF_RS rw — Controls series resistance of AAF
  [2:1] ADC_FF_ADJ rw — Adjust feed forward
  [0] ADC_DAC_ROT rw — Control of DAC DWA scheme 0 = DWA (scrambling) disabled 1 = DWA enabled
0xE0 MDMTEST0 — Test register for modem
  [31:8] Reserved32 ro — This register is 8 bits in a 32-bit address space.
  [7:4] TX_TONE rw — Enables the possibility to transmit a baseband tone by picking samples from the sine tables with a controllable phase step between the samples. The step size is controlled by TX_TONE. If MDMTEST1.MOD_IF is 0, the tone is superpositioned on the modulated data, effectively giving modulation with an IF. If MDMTEST1.MOD_IF is 1, only the tone is transmitted. 0000: -6 MHz 0001: -4 MHz 0010: -3 MHz 0011: -2 MHz 0100: -1 MHz 0101: -500 kHz 0110: -4 kHz 0111: 0 1000: 4 kHz 1001: 500 kHz 1010: 1 MHz 1011: 2 MHz 1100: 3 MHz 1101: 4 MHz 1110: 6 MHz Others: Reserved
  [3:2] DC_WIN_SIZE rw — Controls the numbers of samples to be accumulated between each dump of the accumulate-and-dump filter used in DC removal 00: 32 samples 01: 64 samples 10: 128 samples 11: 256 samples
  [1:0] DC_BLOCK_MODE rw — Selects the mode of operation 00: The input signal to the DC blocker is passed to the output without any attempt to remove DC. 01: Enable DC cancellation. Normal operation 10: Freeze estimates of DC when sync is found. Resume estimating DC when searching for the next frame. 11: Reserved
0xE4 MDMTEST1 — Test Register for Modem
  [31:8] Reserved32 ro — This register is 8 bits in a 32-bit address space.
  [5] USEMIRROR_IF rw — 0: Use the normal IF frequency (MDMTEST0.TX_TONE) for automatic IF compensation of channel frequency on TX. 1: Use mirror IF frequency for automatic compensation of channel frequency on TX.
  [4] MOD_IF rw — 0: Modulation is performed at an IF set by MDMTEST0.TX_TONE. The tone set by MDMTEST0.TX_TONE is superimposed on the data. 1: Modulate a tone set by MDMTEST0.TX_TONE. A tone is transmitted with frequency set by MDMTEST0.TX_TONE.
  [3] RAMP_AMP rw — 1: Enable ramping of DAC output amplitude during startup and finish. 0: Disable ramping of DAC output amplitude.
  [2] RFC_SNIFF_EN rw — 0: Packet sniffer module disabled 1: Packet sniffer module enabled. The received and transmitted data can be observed on GPIO pins.
  [1] Reserved rw — Must be written as 0 for correct operation.
  [0] LOOPBACK_EN rw — Enables loopback of modulated data into the receiver chain 0: An STXCAL instruction calibrates for TX. Use STXON to continue to active TX. 1: An STXCAL instruction enables the loopback mode.
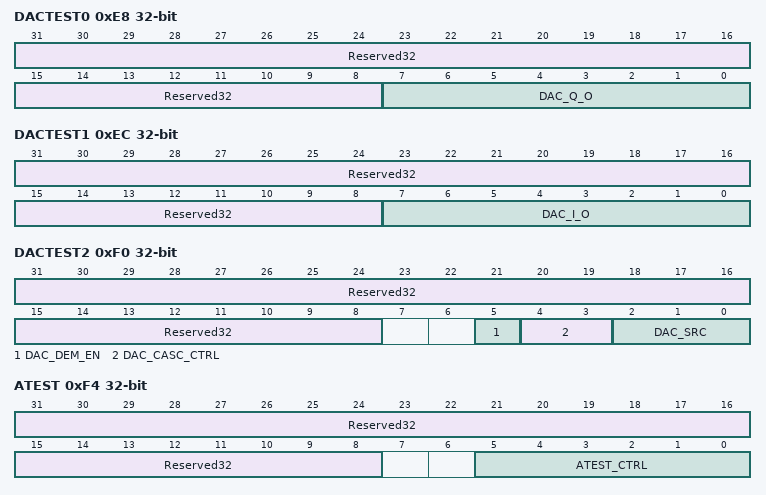
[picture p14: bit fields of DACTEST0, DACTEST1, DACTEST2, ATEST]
0xE8 DACTEST0 — DAC override value
  [31:8] Reserved32 ro — This register is 8 bits in a 32-bit address space.
  [7:0] DAC_Q_O rw — Q-branch DAC override value when DAC_SRC = 001 If DAC_SRC is set to be ADC data, CORDIC magnitude, or channel filtered data, then DAC_Q_O controls the part of the word in question that is actually multiplexed to the DAC, as described below. 000111: Bits 7:0 001000: Bits 8:1 001001: Bits 9:2 ... If an invalid setting is chosen, the DAC outputs only zeros (minimum value).
0xEC DACTEST1 — DAC override value
  [31:8] Reserved32 ro — This register is 8 bits in a 32-bit address space.
  [7:0] DAC_I_O rw — I-branch DAC override value when DAC_SRC = 001 If DAC_SRC is set to be ADC data, CORDIC magnitude, channel filtered data, or DC filtered data, then DAC_I_O controls the part of the word in question that is actually multiplexed to the DAC as described below. 000111: Bits 7:0 001000: Bits 8:1 001001: Bits 9:2 ... If an invalid setting is chosen, then the DAC outputs only zeros (minimum value).
0xF0 DACTEST2 — DAC test setting
  [31:8] Reserved32 ro — This register is 8 bits in a 32-bit address space.
  [5] DAC_DEM_EN rw — Enable and disable dynamic element matching Drives RFR_DAC_DEM_EN
  [4:3] DAC_CASC_CTRL rw — Adjustment of output stage Drives RFR_DAC_CASC_CTRL
  [2:0] DAC_SRC rw — The TX DACs data source is selected by DAC_SRC according to: 000: Normal operation (from modulator) 001: The DAC_I_O and DAC_Q_O override values 010: ADC data after decimation, magnitude controlled by DAC_I_O and DAC_Q_O 011: I/Q after decimation, channel and DC filtering, magnitude controlled by DAC_I_O and DAC_Q_O 100: CORDIC magnitude output and front-end gain is output, magnitude controlled by DAC_I_O and DAC_Q_O 101: RSSI I output on the I DAC 111: Reserved
0xF4 ATEST — Analog test control
  [31:8] Reserved32 rw — This register is 8 bits in a 32-bit address space.
  [5:0] ATEST_CTRL rw — Controls the analog test mode: 00 0000: Disabled 00 0001: Enables the temperature sensor (see also the CCTEST_TR0 register description). Other values reserved.
0xF8 PTEST0 — Override power-down register
  [31:8] Reserved32 ro — This register is 8 bits in a 32-bit address space.
  [7] PRE_PD ro — Prescaler power-down signal When PD_OVERRIDE = 1
  [6] CHP_PD rw — Charge pump power-down signal When PD_OVERRIDE = 1
  [5] ADC_PD rw — ADC power-down signal When PD_OVERRIDE = 1
  [4] DAC_PD rw — DAC power-down signal When PD_OVERRIDE = 1
  [3:2] LNA_PD rw — Low-noise amplifier power-down signal Defines LNA/mixer power-down modes: 00: Power up 01: LNA off, mixer/regulator on 10: LNA/mixer off, regulator on 11: PD When PD_OVERRIDE = 1
  [1] TXMIX_PD rw — Transmit mixer power-down signal When PD_OVERRIDE = 1
  [0] AAF_PD rw — Antialiasing filter power-down signal When PD_OVERRIDE = 1
0xFC PTEST1 — Override power-down register
  [31:8] Reserved32 ro — This register is 8 bits in a 32-bit address space.
  [3] PD_OVERRIDE rw — Override enabling and disabling of various modules (for debug and testing only) It is impossible to override hard-coded BIAS_PD[1:0] depenancy.
  [2] PA_PD rw — Power amplifier power-down signal When PD_OVERRIDE = 1
  [1] VCO_PD rw — VCO power-down signal When PD_OVERRIDE = 1
  [0] LODIV_PD rw — LO power-down signal When PD_OVERRIDE = 1
{0x100+4i} CSPPROG_{i} ro (i=0..23) — CSP program
  [31:8] Reserved32 — This register is 8 bits in a 32-bit address space.
  [7:0] CSP_INSTR — Byte N of the CSP program memory
0x180 CSPCTRL — CSP control bit
  [31:8] Reserved32 ro — This register is 8 bits in a 32-bit address space.
  [0] MCU_CTRL rw — CSP MCU control input
0x184 CSPSTAT ro — CSP status register
  [31:8] Reserved32 — This register is 8 bits in a 32-bit address space.
  [5] CSP_RUNNING — 1: CSP is running. 0: CSP is idle.
  [4:0] CSP_PC — CSP program counter
0x188 CSPX ro — CSP X data register
  [31:8] Reserved32 — This register is 8 bits in a 32-bit address space.
  [7:0] CSPX — Used by CSP instructions WAITX, RANDXY, INCX, DECX, and conditional instructions.
0x18C CSPY ro — CSP Y data register
  [31:8] Reserved32 — This register is 8 bits in a 32-bit address space.
  [7:0] CSPY — Used by CSP instructions RANDXY, INCY, DECY, and conditional instructions.
0x190 CSPZ ro — CSP Z data register
  [31:8] Reserved32 — This register is 8 bits in a 32-bit address space.
  [7:0] CSPZ — Used by CSP instructions INCZ, DECZ, and conditional instructions.
0x194 CSPT ro — CSP T data register
  [31:8] Reserved32 — This register is 8 bits in a 32-bit address space.
  [7:0] CSPT — Content is decremented each time the MAC Timer overflows while the CSP program is running. The SCP program stops when decremented to 0. Setting CSPT = 0xFF prevents the register from being decremented.
0x1AC RFC_OBS_CTRL0 — RF observation mux control
  [31:8] Reserved32 rw — This register is 8 bits in a 32-bit address space.
  [6] RFC_OBS_POL0 rw — The signal chosen by RFC_OBS_MUX0 is XORed with this bit.
  [5:0] RFC_OBS_MUX0 rw — Controls which observable signal from RF Core is to be muxed out to rfc_obs_sigs[0]. 00 0000: 0 - Constant value 00 0001: 1 - Constant value 00 1000: rfc_sniff_data - Data from packet sniffer. Sample data on rising edges of sniff_clk. 00 1001: rfc_sniff_clk - 250kHz clock for packet sniffer data. 00 1100: rssi_valid - Pin is high when the RSSI value has been updated at least once since RX was started. Cleared when leaving RX. 00 1101: demod_cca - Clear channel assessment. See FSMSTAT1 register for details on how to configure the behavior of this signal. 00 1110: sampled_cca - A sampled version of the CCA bit from demodulator. The value is updated whenever a SSAMPLECCA or STXONCCA strobe is issued. 00 1111: sfd_sync - Pin is high when a SFD has been received or transmitted. Cleared when leaving RX/TX respectively. Not to be confused with the SFD exception. 01 0000: tx_active - Indicates that FFCTRL is in one of the TX states. Active-high. Note: This signal might have glitches, because it has no output flip-flop and is based on the current state register of the FFCTRL FSM. 01 0001: rx_active - Indicates that FFCTRL is in one of the RX states. Active-high. Note: This signal might have glitches, because it has no output flip-flop and is based on the current state register of the FFCTRL FSM. 01 0010: ffctrl_fifo - Pin is high when one or more bytes are in the RXFIFO. Low during RXFIFO overflow. 01 0011: ffctrl_fifop - Pin is high when the number of bytes in the RXFIFO exceeds the programmable threshold or at least one complete frame is in the RXFIFO. Also high during RXFIFO overflow. Not to be confused with the FIFOP exception. 01 0100: packet_done - A complete frame has been received. I.e., the number of bytes set by the frame-length field has been received. 01 0110: rfc_xor_rand_i_q - XOR between I and Q random outputs. Updated at 8 MHz. 01 0111: rfc_rand_q - Random data output from the Q channel of the receiver. Updated at 8 MHz. 01 1000: rfc_rand_i - Random data output from the I channel of the receiver. Updated at 8 MHz 01 1001: lock_status - 1 when PLL is in lock, otherwise 0 10 1000: pa_pd - Power amplifier power-down signal 10 1010: lna_pd - LNA power-down signal Others: Reserved
0x1B0 RFC_OBS_CTRL1 — RF observation mux control
  [31:8] Reserved32 rw — This register is 8 bits in a 32-bit address space.
  [6] RFC_OBS_POL1 rw — The signal chosen by RFC_OBS_MUX1 is XORed with this bit.
  [5:0] RFC_OBS_MUX1 rw — Controls which observable signal from RF Core is to be muxed out to rfc_obs_sigs[1]. See description of RFC_OBS_CTRL0 for details.
0x1B4 RFC_OBS_CTRL2 — RF observation mux control
  [31:8] Reserved32 ro — This register is 8 bits in a 32-bit address space.
  [6] RFC_OBS_POL2 rw — The signal chosen by RFC_OBS_MUX2 is XORed with this bit.
  [5:0] RFC_OBS_MUX2 rw — Controls which observable signal from RF Core is to be muxed out to rfc_obs_sigs[2]. See description of RFC_OBS_CTRL0 for details.
0x1E8 TXFILTCFG — TX filter configuration
  [31:8] Reserved32 ro — This register is 8 bits in a 32-bit address space.
  [3:0] FC rw — Drives signal rfr_txfilt_fc
